# ATSAM4SP32A device description
Architecture: CORTEX-M4; Family: SAM4; Series: SAM4SP
Registers are 32-bit, read-write, no defined reset value unless marked. A register's access mark holds for its fields unless they carry their own. Offsets are from the block's base; [hi:lo] are bit positions.

## PPLC — PRIME Power Line Communication (PPLC) Transceiver
Instances: PPLC 0x40008000
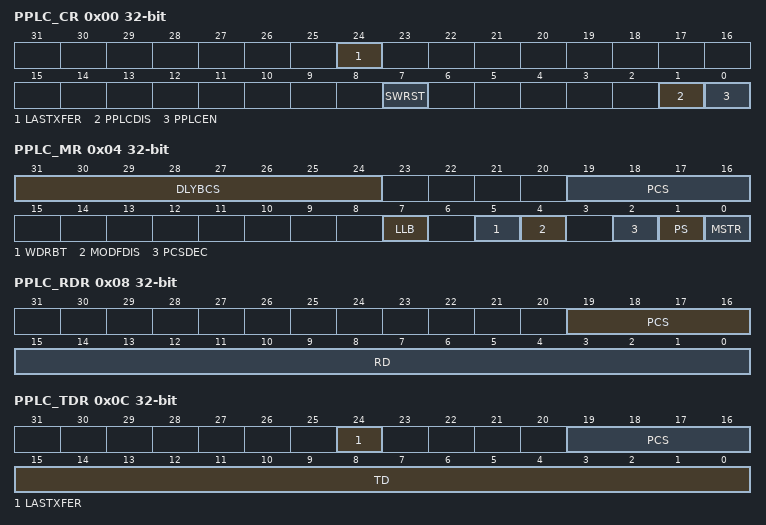
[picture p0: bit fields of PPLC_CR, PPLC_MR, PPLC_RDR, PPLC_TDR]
0x00 PPLC_CR wo — Control Register
  [24] LASTXFER — Last Transfer
  [7] SWRST — PPLC Software Reset
  [1] PPLCDIS — PPLC Disable
  [0] PPLCEN — PPLC Enable
0x04 PPLC_MR — Mode Register
  [31:24] DLYBCS — Delay Between Chip Selects
  [19:16] PCS — Peripheral Chip Select
  [7] LLB — Local Loopback Enable
  [5] WDRBT — Wait Data Read Before Transfer
  [4] MODFDIS — Mode Fault Detection
  [2] PCSDEC — Chip Select Decode
  [1] PS — Peripheral Select
  [0] MSTR — Active Mode
0x08 PPLC_RDR ro — Receive Data Register
  [19:16] PCS — Peripheral Chip Select
  [15:0] RD — Receive Data
0x0C PPLC_TDR wo — Transmit Data Register
  [24] LASTXFER — Last Transfer
  [19:16] PCS — Peripheral Chip Select
  [15:0] TD — Transmit Data
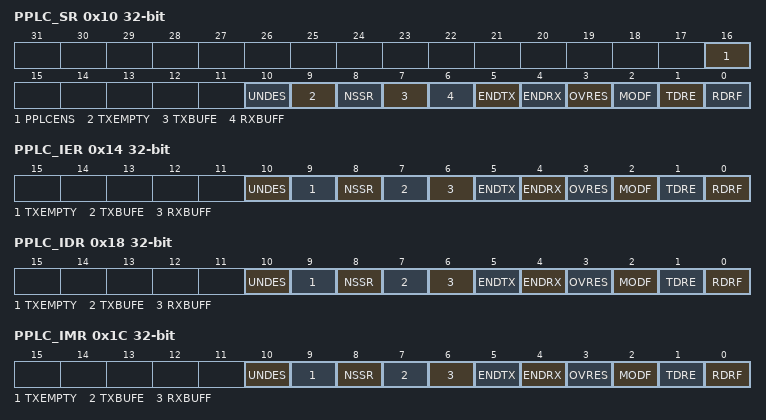
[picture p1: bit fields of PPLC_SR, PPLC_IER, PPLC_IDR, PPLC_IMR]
0x10 PPLC_SR ro — Status Register
  [16] PPLCENS — PPLC Enable Status
  [10] UNDES — Underrun Error Status (Slave Mode Only)
  [9] TXEMPTY — Transmission Registers Empty
  [8] NSSR — NSS Rising
  [7] TXBUFE — TX Buffer Empty
  [6] RXBUFF — RX Buffer Full
  [5] ENDTX — End of TX buffer
  [4] ENDRX — End of RX buffer
  [3] OVRES — Overrun Error Status
  [2] MODF — Mode Fault Error
  [1] TDRE — Transmit Data Register Empty
  [0] RDRF — Receive Data Register Full
0x14 PPLC_IER wo — Interrupt Enable Register
  [10] UNDES — Underrun Error Interrupt Enable
  [9] TXEMPTY — Transmission Registers Empty Enable
  [8] NSSR — NSS Rising Interrupt Enable
  [7] TXBUFE — Transmit Buffer Empty Interrupt Enable
  [6] RXBUFF — Receive Buffer Full Interrupt Enable
  [5] ENDTX — End of Transmit Buffer Interrupt Enable
  [4] ENDRX — End of Receive Buffer Interrupt Enable
  [3] OVRES — Overrun Error Interrupt Enable
  [2] MODF — Mode Fault Error Interrupt Enable
  [1] TDRE — PPLC Transmit Data Register Empty Interrupt Enable
  [0] RDRF — Receive Data Register Full Interrupt Enable
0x18 PPLC_IDR wo — Interrupt Disable Register
  [10] UNDES — Underrun Error Interrupt Disable
  [9] TXEMPTY — Transmission Registers Empty Disable
  [8] NSSR — NSS Rising Interrupt Disable
  [7] TXBUFE — Transmit Buffer Empty Interrupt Disable
  [6] RXBUFF — Receive Buffer Full Interrupt Disable
  [5] ENDTX — End of Transmit Buffer Interrupt Disable
  [4] ENDRX — End of Receive Buffer Interrupt Disable
  [3] OVRES — Overrun Error Interrupt Disable
  [2] MODF — Mode Fault Error Interrupt Disable
  [1] TDRE — PPLC Transmit Data Register Empty Interrupt Disable
  [0] RDRF — Receive Data Register Full Interrupt Disable
0x1C PPLC_IMR ro — Interrupt Mask Register
  [10] UNDES — Underrun Error Interrupt Mask
  [9] TXEMPTY — Transmission Registers Empty Mask
  [8] NSSR — NSS Rising Interrupt Mask
  [7] TXBUFE — Transmit Buffer Empty Interrupt Mask
  [6] RXBUFF — Receive Buffer Full Interrupt Mask
  [5] ENDTX — End of Transmit Buffer Interrupt Mask
  [4] ENDRX — End of Receive Buffer Interrupt Mask
  [3] OVRES — Overrun Error Interrupt Mask
  [2] MODF — Mode Fault Error Interrupt Mask
  [1] TDRE — PPLC Transmit Data Register Empty Interrupt Mask
  [0] RDRF — Receive Data Register Full Interrupt Mask
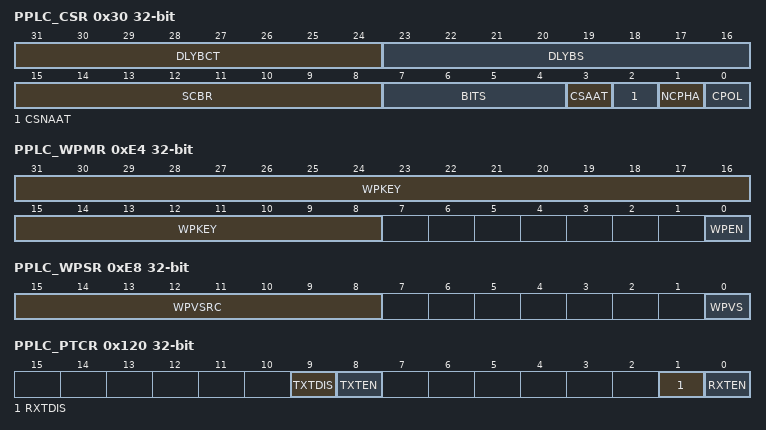
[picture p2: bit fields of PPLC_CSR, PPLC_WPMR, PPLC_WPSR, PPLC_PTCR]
0x30 PPLC_CSR — Chip Select Register
  [31:24] DLYBCT — Delay Between Consecutive Transfers
  [23:16] DLYBS — Delay Before SPCK
  [15:8] SCBR — Serial Clock Baud Rate
  [7:4] BITS — Bits Per Transfer
  [3] CSAAT — Chip Select Active After Transfer
  [2] CSNAAT — Chip Select Not Active After Transfer (Ignored if CSAAT = 1)
  [1] NCPHA — Clock Phase
  [0] CPOL — Clock Polarity
0xE4 PPLC_WPMR — Write Protection Control Register
  [31:8] WPKEY — Write Protection Key Password
  [0] WPEN — Write Protection Enable
0xE8 PPLC_WPSR ro — Write Protection Status Register
  [15:8] WPVSRC — Write Protection Violation Source
  [0] WPVS — Write Protection Violation Status
0x100 PPLC_RPR — Receive Pointer Register
  [31:0] RXPTR
0x104 PPLC_RCR — Receive Counter Register
  [15:0] RXCTR
0x108 PPLC_TPR — Transmit Pointer Register
  [31:0] TXPTR — Transmit Counter Register
0x10C PPLC_TCR — Transmit Counter Register
  [15:0] TXCTR
0x110 PPLC_RNPR — Receive Next Pointer Register
  [31:0] RXNPTR — Receive Next Pointer
0x114 PPLC_RNCR — Receive Next Counter Register
  [15:0] RXNCTR — Receive Next Counter
0x118 PPLC_TNPR — Transmit Next Pointer Register
  [31:0] TXNPTR — Transmit Next Pointer
0x11C PPLC_TNCR — Transmit Next Counter Register
  [15:0] TXNCTR — Transmit Counter Next
0x120 PPLC_PTCR wo — Transfer Control Register
  [9] TXTDIS — Transmitter Transfer Disable
  [8] TXTEN — Transmitter Transfer Enable
  [1] RXTDIS — Receiver Transfer Disable
  [0] RXTEN — Receiver Transfer Enable
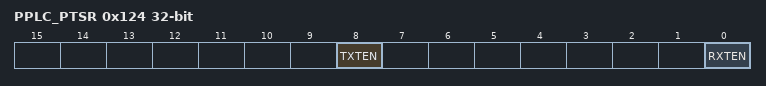
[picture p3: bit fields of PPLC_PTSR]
0x124 PPLC_PTSR ro — Transfer Status Register
  [8] TXTEN — Transmitter Transfer Enable
  [0] RXTEN — Receiver Transfer Enable
